# AST1080 register map
File version: 1.0
CPU: CM4 r0p1, little endian, MPU, FPU, 4 interrupt priority bits, 256 interrupts
Registers are 32-bit, read-write, reset 0x0 unless marked. A register's access mark holds for its fields unless they carry their own. Offsets are from the block's base; [hi:lo] are bit positions; {n}, {i} and the like mark numbered series.

## pric_io (part 1 of 3)
Base 0x74100000
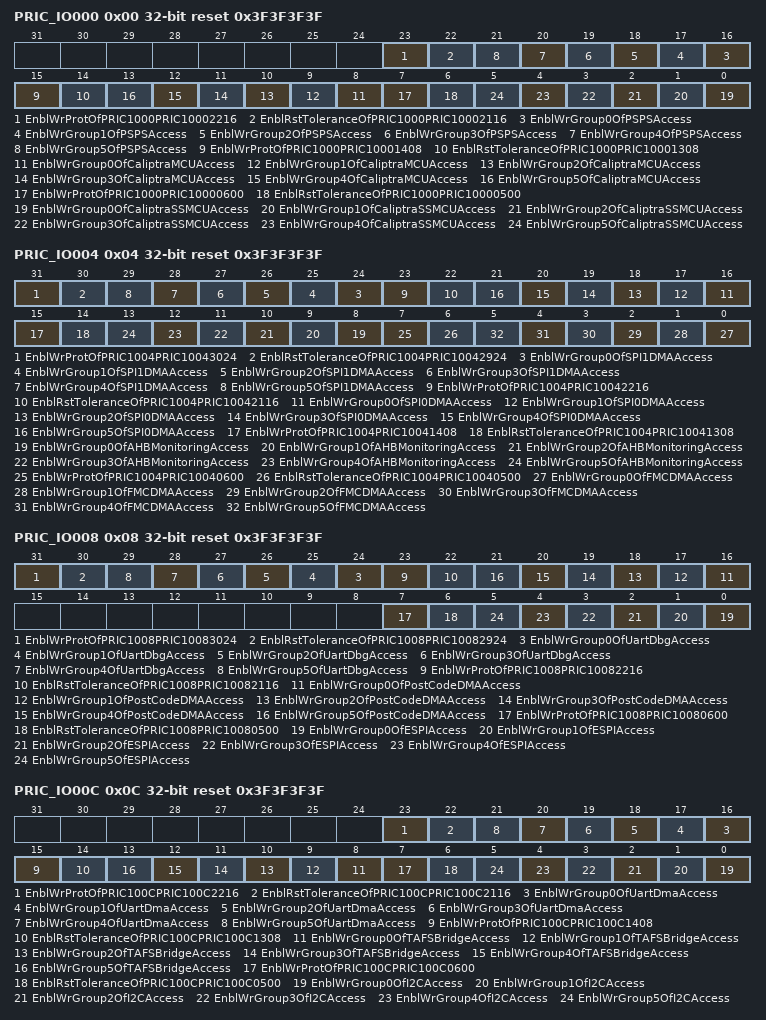
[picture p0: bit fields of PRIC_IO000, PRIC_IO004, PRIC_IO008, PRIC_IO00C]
0x00 PRIC_IO000 reset 0x3F3F3F3F — Master Write Group Setting Register \#0
  [23] EnblWrProtOfPRIC1000PRIC10002216 — Enable Write Protection of PRIC1000PRIC1_000[22:16]
  [22] EnblRstToleranceOfPRIC1000PRIC10002116 — Enable Reset Tolerance of PRIC1000PRIC1_000[21:16]
    0=Reset_By_SRST; 1=Reset_By_SRST_And_PSP_Reset
  [n+16] EnblWrGroup{n}OfPSPSAccess (n=0..5) — Enable Write Group #{n} of PSP-S access
  [15] EnblWrProtOfPRIC1000PRIC10001408 — Enable Write Protection of PRIC1000PRIC1_000[14:08]
  [14] EnblRstToleranceOfPRIC1000PRIC10001308 — Enable Reset Tolerance of PRIC1000PRIC1_000[13:08]
    0=Reset_By_SRST; 1=Reset_By_SRST_And_PSP_Reset
  [n+8] EnblWrGroup{n}OfCaliptraMCUAccess (n=0..5) — Enable Write Group #{n} of Caliptra MCU access
  [7] EnblWrProtOfPRIC1000PRIC10000600 — Enable Write Protection of PRIC1000PRIC1_000[06:00]
  [6] EnblRstToleranceOfPRIC1000PRIC10000500 — Enable Reset Tolerance of PRIC1000PRIC1_000[05:00]
    0=Reset_By_SRST; 1=Reset_By_SRST_And_PSP_Reset
  [n] EnblWrGroup{n}OfCaliptraSSMCUAccess (n=0..5) — Enable Write Group #{n} of Caliptra SS MCU access
0x04 PRIC_IO004 reset 0x3F3F3F3F — Master Write Group Setting Register \#1
  [31] EnblWrProtOfPRIC1004PRIC10043024 — Enable Write Protection of PRIC1004PRIC1_004[30:24]
  [30] EnblRstToleranceOfPRIC1004PRIC10042924 — Enable Reset Tolerance of PRIC1004PRIC1_004[29:24]
    0=Reset_By_SRST; 1=Reset_By_SRST_And_PSP_Reset
  [n+24] EnblWrGroup{n}OfSPI1DMAAccess (n=0..5) — Enable Write Group #{n} of SPI1 DMA access
  [23] EnblWrProtOfPRIC1004PRIC10042216 — Enable Write Protection of PRIC1004PRIC1_004[22:16]
  [22] EnblRstToleranceOfPRIC1004PRIC10042116 — Enable Reset Tolerance of PRIC1004PRIC1_004[21:16]
    0=Reset_By_SRST; 1=Reset_By_SRST_And_PSP_Reset
  [n+16] EnblWrGroup{n}OfSPI0DMAAccess (n=0..5) — Enable Write Group #{n} of SPI0 DMA access
  [15] EnblWrProtOfPRIC1004PRIC10041408 — Enable Write Protection of PRIC1004PRIC1_004[14:08]
  [14] EnblRstToleranceOfPRIC1004PRIC10041308 — Enable Reset Tolerance of PRIC1004PRIC1_004[13:08]
    0=Reset_By_SRST; 1=Reset_By_SRST_And_PSP_Reset
  [n+8] EnblWrGroup{n}OfAHBMonitoringAccess (n=0..5) — Enable Write Group #{n} of AHB Monitoring access
  [7] EnblWrProtOfPRIC1004PRIC10040600 — Enable Write Protection of PRIC1004PRIC1_004[06:00]
  [6] EnblRstToleranceOfPRIC1004PRIC10040500 — Enable Reset Tolerance of PRIC1004PRIC1_004[05:00]
    0=Reset_By_SRST; 1=Reset_By_SRST_And_PSP_Reset
  [n] EnblWrGroup{n}OfFMCDMAAccess (n=0..5) — Enable Write Group #{n} of FMC DMA access
0x08 PRIC_IO008 reset 0x3F3F3F3F — Master Write Group Setting Register \#2
  [31] EnblWrProtOfPRIC1008PRIC10083024 — Enable Write Protection of PRIC1008PRIC1_008[30:24]
  [30] EnblRstToleranceOfPRIC1008PRIC10082924 — Enable Reset Tolerance of PRIC1008PRIC1_008[29:24]
    0=Reset_By_SRST; 1=Reset_By_SRST_And_PSP_Reset
  [n+24] EnblWrGroup{n}OfUartDbgAccess (n=0..5) — Enable Write Group #{n} of UartDbg access
  [23] EnblWrProtOfPRIC1008PRIC10082216 — Enable Write Protection of PRIC1008PRIC1_008[22:16]
  [22] EnblRstToleranceOfPRIC1008PRIC10082116 — Enable Reset Tolerance of PRIC1008PRIC1_008[21:16]
    0=Reset_By_SRST; 1=Reset_By_SRST_And_PSP_Reset
  [n+16] EnblWrGroup{n}OfPostCodeDMAAccess (n=0..5) — Enable Write Group #{n} of PostCode DMA access
  [7] EnblWrProtOfPRIC1008PRIC10080600 — Enable Write Protection of PRIC1008PRIC1_008[06:00]
  [6] EnblRstToleranceOfPRIC1008PRIC10080500 — Enable Reset Tolerance of PRIC1008PRIC1_008[05:00]
    0=Reset_By_SRST; 1=Reset_By_SRST_And_PSP_Reset
  [n] EnblWrGroup{n}OfESPIAccess (n=0..5) — Enable Write Group #{n} of eSPI access
0x0C PRIC_IO00C reset 0x3F3F3F3F — Master Write Group Setting Register \#3
  [23] EnblWrProtOfPRIC100CPRIC100C2216 — Enable Write Protection of PRIC100CPRIC1_00C[22:16]
  [22] EnblRstToleranceOfPRIC100CPRIC100C2116 — Enable Reset Tolerance of PRIC100CPRIC1_00C[21:16]
    0=Reset_By_SRST; 1=Reset_By_SRST_And_PSP_Reset
  [n+16] EnblWrGroup{n}OfUartDmaAccess (n=0..5) — Enable Write Group #{n} of UartDma access
  [15] EnblWrProtOfPRIC100CPRIC100C1408 — Enable Write Protection of PRIC100CPRIC1_00C[14:08]
  [14] EnblRstToleranceOfPRIC100CPRIC100C1308 — Enable Reset Tolerance of PRIC100CPRIC1_00C[13:08]
    0=Reset_By_SRST; 1=Reset_By_SRST_And_PSP_Reset
  [n+8] EnblWrGroup{n}OfTAFSBridgeAccess (n=0..5) — Enable Write Group #{n} of TAFS Bridge access
  [7] EnblWrProtOfPRIC100CPRIC100C0600 — Enable Write Protection of PRIC100CPRIC1_00C[06:00]
  [6] EnblRstToleranceOfPRIC100CPRIC100C0500 — Enable Reset Tolerance of PRIC100CPRIC1_00C[05:00]
    0=Reset_By_SRST; 1=Reset_By_SRST_And_PSP_Reset
  [n] EnblWrGroup{n}OfI2CAccess (n=0..5) — Enable Write Group #{n} of I2C access
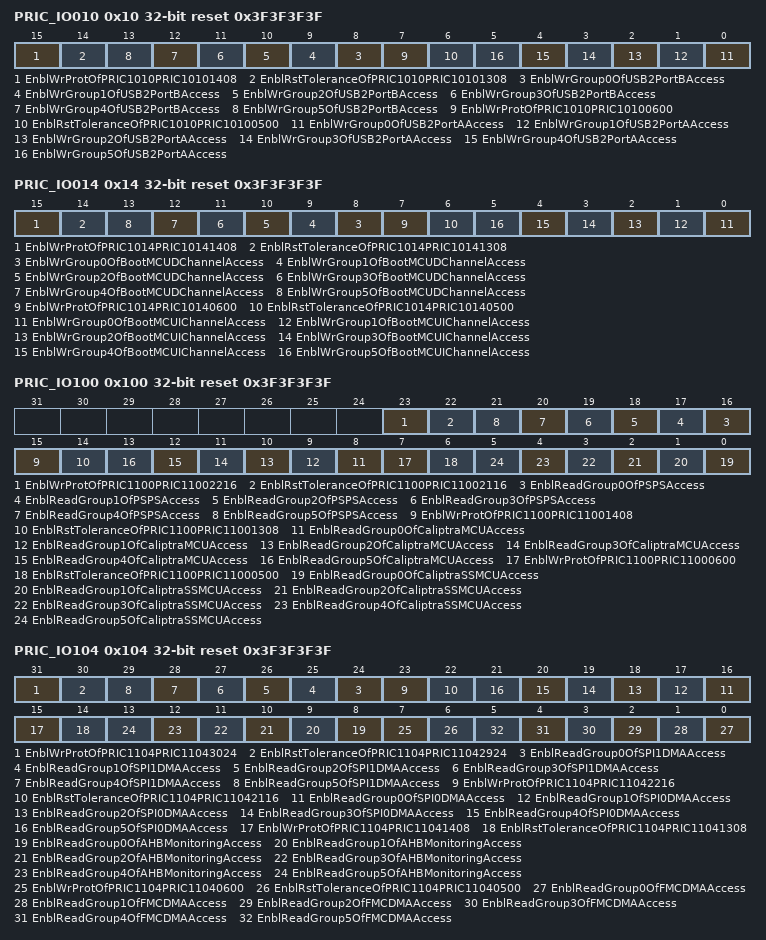
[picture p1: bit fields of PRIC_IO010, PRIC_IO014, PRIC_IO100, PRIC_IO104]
0x10 PRIC_IO010 reset 0x3F3F3F3F — Master Write Group Setting Register \#4
  [15] EnblWrProtOfPRIC1010PRIC10101408 — Enable Write Protection of PRIC1010PRIC1_010[14:08]
  [14] EnblRstToleranceOfPRIC1010PRIC10101308 — Enable Reset Tolerance of PRIC1010PRIC1_010[13:08]
    0=Reset_By_SRST; 1=Reset_By_SRST_And_PSP_Reset
  [n+8] EnblWrGroup{n}OfUSB2PortBAccess (n=0..5) — Enable Write Group #{n} of USB2 Port B access
  [7] EnblWrProtOfPRIC1010PRIC10100600 — Enable Write Protection of PRIC1010PRIC1_010[06:00]
  [6] EnblRstToleranceOfPRIC1010PRIC10100500 — Enable Reset Tolerance of PRIC1010PRIC1_010[05:00]
    0=Reset_By_SRST; 1=Reset_By_SRST_And_PSP_Reset
  [n] EnblWrGroup{n}OfUSB2PortAAccess (n=0..5) — Enable Write Group #{n} of USB2 Port A access
0x14 PRIC_IO014 reset 0x3F3F3F3F — Master Write Group Setting Register \#5
  [15] EnblWrProtOfPRIC1014PRIC10141408 — Enable Write Protection of PRIC1014PRIC1_014[14:08]
  [14] EnblRstToleranceOfPRIC1014PRIC10141308 — Enable Reset Tolerance of PRIC1014PRIC1_014[13:08]
    0=Reset_By_SRST; 1=Reset_By_SRST_And_PSP_Reset
  [n+8] EnblWrGroup{n}OfBootMCUDChannelAccess (n=0..5) — Enable Write Group #{n} of Boot MCU D channel access
  [7] EnblWrProtOfPRIC1014PRIC10140600 — Enable Write Protection of PRIC1014PRIC1_014[06:00]
  [6] EnblRstToleranceOfPRIC1014PRIC10140500 — Enable Reset Tolerance of PRIC1014PRIC1_014[05:00]
    0=Reset_By_SRST; 1=Reset_By_SRST_And_PSP_Reset
  [n] EnblWrGroup{n}OfBootMCUIChannelAccess (n=0..5) — Enable Write Group #{n} of Boot MCU I channel access
0x100 PRIC_IO100 reset 0x3F3F3F3F — Master Read Group Setting Register \#0
  [23] EnblWrProtOfPRIC1100PRIC11002216 — Enable Write Protection of PRIC1100PRIC1_100[22:16]
  [22] EnblRstToleranceOfPRIC1100PRIC11002116 — Enable Reset Tolerance of PRIC1100PRIC1_100[21:16]
    0=Reset_By_SRST; 1=Reset_By_SRST_And_PSP_Reset
  [n+16] EnblReadGroup{n}OfPSPSAccess (n=0..5) — Enable Read Group #{n} of PSP-S access
  [15] EnblWrProtOfPRIC1100PRIC11001408 — Enable Write Protection of PRIC1100PRIC1_100[14:08]
  [14] EnblRstToleranceOfPRIC1100PRIC11001308 — Enable Reset Tolerance of PRIC1100PRIC1_100[13:08]
    0=Reset_By_SRST; 1=Reset_By_SRST_And_PSP_Reset
  [n+8] EnblReadGroup{n}OfCaliptraMCUAccess (n=0..5) — Enable Read Group #{n} of Caliptra MCU access
  [7] EnblWrProtOfPRIC1100PRIC11000600 — Enable Write Protection of PRIC1100PRIC1_100[06:00]
  [6] EnblRstToleranceOfPRIC1100PRIC11000500 — Enable Reset Tolerance of PRIC1100PRIC1_100[05:00]
    0=Reset_By_SRST; 1=Reset_By_SRST_And_PSP_Reset
  [n] EnblReadGroup{n}OfCaliptraSSMCUAccess (n=0..5) — Enable Read Group #{n} of Caliptra SS MCU access
0x104 PRIC_IO104 reset 0x3F3F3F3F — Master Read Group Setting Register \#1
  [31] EnblWrProtOfPRIC1104PRIC11043024 — Enable Write Protection of PRIC1104PRIC1_104[30:24]
  [30] EnblRstToleranceOfPRIC1104PRIC11042924 — Enable Reset Tolerance of PRIC1104PRIC1_104[29:24]
    0=Reset_By_SRST; 1=Reset_By_SRST_And_PSP_Reset
  [n+24] EnblReadGroup{n}OfSPI1DMAAccess (n=0..5) — Enable Read Group #{n} of SPI1 DMA access
  [23] EnblWrProtOfPRIC1104PRIC11042216 — Enable Write Protection of PRIC1104PRIC1_104[22:16]
  [22] EnblRstToleranceOfPRIC1104PRIC11042116 — Enable Reset Tolerance of PRIC1104PRIC1_104[21:16]
    0=Reset_By_SRST; 1=Reset_By_SRST_And_PSP_Reset
  [n+16] EnblReadGroup{n}OfSPI0DMAAccess (n=0..5) — Enable Read Group #{n} of SPI0 DMA access
  [15] EnblWrProtOfPRIC1104PRIC11041408 — Enable Write Protection of PRIC1104PRIC1_104[14:08]
  [14] EnblRstToleranceOfPRIC1104PRIC11041308 — Enable Reset Tolerance of PRIC1104PRIC1_104[13:08]
    0=Reset_By_SRST; 1=Reset_By_SRST_And_PSP_Reset
  [n+8] EnblReadGroup{n}OfAHBMonitoringAccess (n=0..5) — Enable Read Group #{n} of AHB Monitoring access
  [7] EnblWrProtOfPRIC1104PRIC11040600 — Enable Write Protection of PRIC1104PRIC1_104[06:00]
  [6] EnblRstToleranceOfPRIC1104PRIC11040500 — Enable Reset Tolerance of PRIC1104PRIC1_104[05:00]
    0=Reset_By_SRST; 1=Reset_By_SRST_And_PSP_Reset
  [n] EnblReadGroup{n}OfFMCDMAAccess (n=0..5) — Enable Read Group #{n} of FMC DMA access
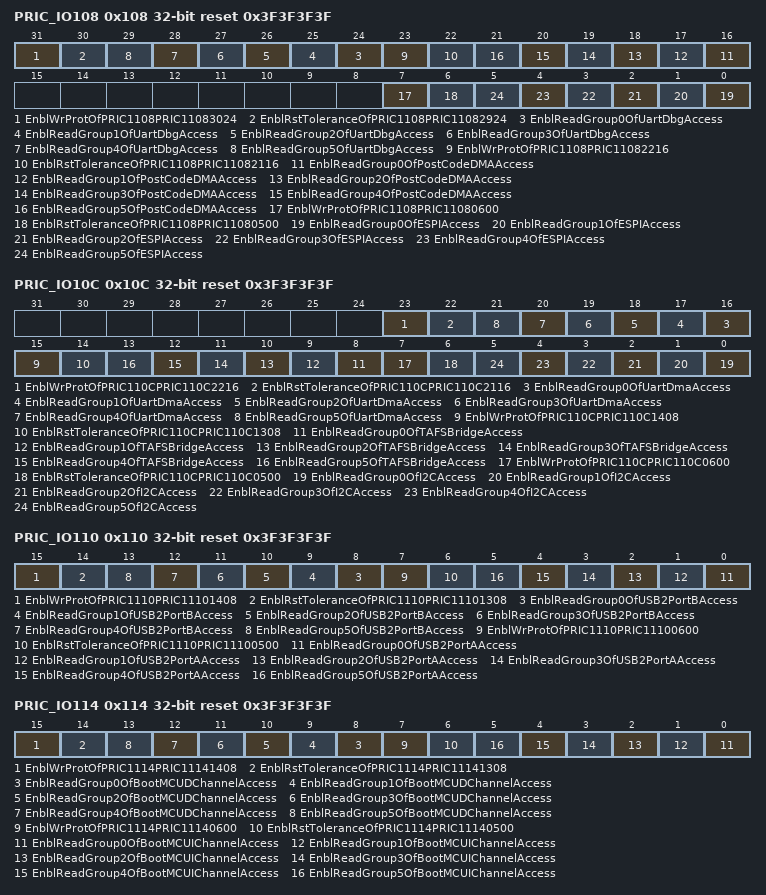
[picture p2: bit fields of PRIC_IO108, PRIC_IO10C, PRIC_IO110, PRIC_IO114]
0x108 PRIC_IO108 reset 0x3F3F3F3F — Master Read Group Setting Register \#2
  [31] EnblWrProtOfPRIC1108PRIC11083024 — Enable Write Protection of PRIC1108PRIC1_108[30:24]
  [30] EnblRstToleranceOfPRIC1108PRIC11082924 — Enable Reset Tolerance of PRIC1108PRIC1_108[29:24]
    0=Reset_By_SRST; 1=Reset_By_SRST_And_PSP_Reset
  [n+24] EnblReadGroup{n}OfUartDbgAccess (n=0..5) — Enable Read Group #{n} of UartDbg access
  [23] EnblWrProtOfPRIC1108PRIC11082216 — Enable Write Protection of PRIC1108PRIC1_108[22:16]
  [22] EnblRstToleranceOfPRIC1108PRIC11082116 — Enable Reset Tolerance of PRIC1108PRIC1_108[21:16]
    0=Reset_By_SRST; 1=Reset_By_SRST_And_PSP_Reset
  [n+16] EnblReadGroup{n}OfPostCodeDMAAccess (n=0..5) — Enable Read Group #{n} of PostCode DMA access
  [7] EnblWrProtOfPRIC1108PRIC11080600 — Enable Write Protection of PRIC1108PRIC1_108[06:00]
  [6] EnblRstToleranceOfPRIC1108PRIC11080500 — Enable Reset Tolerance of PRIC1108PRIC1_108[05:00]
    0=Reset_By_SRST; 1=Reset_By_SRST_And_PSP_Reset
  [n] EnblReadGroup{n}OfESPIAccess (n=0..5) — Enable Read Group #{n} of eSPI access
0x10C PRIC_IO10C reset 0x3F3F3F3F — Master Read Group Setting Register \#3
  [23] EnblWrProtOfPRIC110CPRIC110C2216 — Enable Write Protection of PRIC110CPRIC1_10C[22:16]
  [22] EnblRstToleranceOfPRIC110CPRIC110C2116 — Enable Reset Tolerance of PRIC110CPRIC1_10C[21:16]
    0=Reset_By_SRST; 1=Reset_By_SRST_And_PSP_Reset
  [n+16] EnblReadGroup{n}OfUartDmaAccess (n=0..5) — Enable Read Group #{n} of UartDma access
  [15] EnblWrProtOfPRIC110CPRIC110C1408 — Enable Write Protection of PRIC110CPRIC1_10C[14:08]
  [14] EnblRstToleranceOfPRIC110CPRIC110C1308 — Enable Reset Tolerance of PRIC110CPRIC1_10C[13:08]
    0=Reset_By_SRST; 1=Reset_By_SRST_And_PSP_Reset
  [n+8] EnblReadGroup{n}OfTAFSBridgeAccess (n=0..5) — Enable Read Group #{n} of TAFS Bridge access
  [7] EnblWrProtOfPRIC110CPRIC110C0600 — Enable Write Protection of PRIC110CPRIC1_10C[06:00]
  [6] EnblRstToleranceOfPRIC110CPRIC110C0500 — Enable Reset Tolerance of PRIC110CPRIC1_10C[05:00]
    0=Reset_By_SRST; 1=Reset_By_SRST_And_PSP_Reset
  [n] EnblReadGroup{n}OfI2CAccess (n=0..5) — Enable Read Group #{n} of I2C access
0x110 PRIC_IO110 reset 0x3F3F3F3F — Master Read Group Setting Register \#4
  [15] EnblWrProtOfPRIC1110PRIC11101408 — Enable Write Protection of PRIC1110PRIC1_110[14:08]
  [14] EnblRstToleranceOfPRIC1110PRIC11101308 — Enable Reset Tolerance of PRIC1110PRIC1_110[13:08]
    0=Reset_By_SRST; 1=Reset_By_SRST_And_PSP_Reset
  [n+8] EnblReadGroup{n}OfUSB2PortBAccess (n=0..5) — Enable Read Group #{n} of USB2 Port B access
  [7] EnblWrProtOfPRIC1110PRIC11100600 — Enable Write Protection of PRIC1110PRIC1_110[06:00]
  [6] EnblRstToleranceOfPRIC1110PRIC11100500 — Enable Reset Tolerance of PRIC1110PRIC1_110[05:00]
    0=Reset_By_SRST; 1=Reset_By_SRST_And_PSP_Reset
  [n] EnblReadGroup{n}OfUSB2PortAAccess (n=0..5) — Enable Read Group #{n} of USB2 Port A access
0x114 PRIC_IO114 reset 0x3F3F3F3F — Master Read Group Setting Register \#5
  [15] EnblWrProtOfPRIC1114PRIC11141408 — Enable Write Protection of PRIC1114PRIC1_114[14:08]
  [14] EnblRstToleranceOfPRIC1114PRIC11141308 — Enable Reset Tolerance of PRIC1114PRIC1_114[13:08]
    0=Reset_By_SRST; 1=Reset_By_SRST_And_PSP_Reset
  [n+8] EnblReadGroup{n}OfBootMCUDChannelAccess (n=0..5) — Enable Read Group #{n} of Boot MCU D channel access
  [7] EnblWrProtOfPRIC1114PRIC11140600 — Enable Write Protection of PRIC1114PRIC1_114[06:00]
  [6] EnblRstToleranceOfPRIC1114PRIC11140500 — Enable Reset Tolerance of PRIC1114PRIC1_114[05:00]
    0=Reset_By_SRST; 1=Reset_By_SRST_And_PSP_Reset
  [n] EnblReadGroup{n}OfBootMCUIChannelAccess (n=0..5) — Enable Read Group #{n} of Boot MCU I channel access
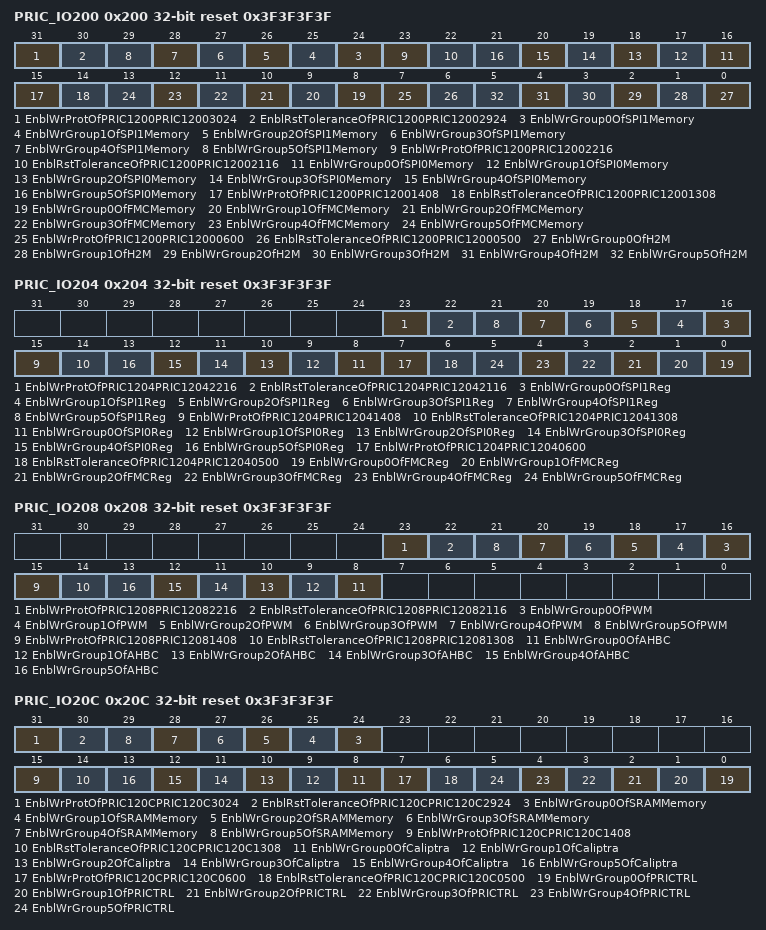
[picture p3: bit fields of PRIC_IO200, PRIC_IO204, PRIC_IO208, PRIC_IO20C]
0x200 PRIC_IO200 reset 0x3F3F3F3F — Slave Write Group Setting Register \#0
  [31] EnblWrProtOfPRIC1200PRIC12003024 — Enable Write Protection of PRIC1200PRIC1_200[30:24]
  [30] EnblRstToleranceOfPRIC1200PRIC12002924 — Enable Reset Tolerance of PRIC1200PRIC1_200[29:24]
    0=Reset_By_SRST; 1=Reset_By_SRST_And_PSP_Reset
  [n+24] EnblWrGroup{n}OfSPI1Memory (n=0..5) — Enable Write Group #{n} of SPI1 Memory
  [23] EnblWrProtOfPRIC1200PRIC12002216 — Enable Write Protection of PRIC1200PRIC1_200[22:16]
  [22] EnblRstToleranceOfPRIC1200PRIC12002116 — Enable Reset Tolerance of PRIC1200PRIC1_200[21:16]
    0=Reset_By_SRST; 1=Reset_By_SRST_And_PSP_Reset
  [n+16] EnblWrGroup{n}OfSPI0Memory (n=0..5) — Enable Write Group #{n} of SPI0 Memory
  [15] EnblWrProtOfPRIC1200PRIC12001408 — Enable Write Protection of PRIC1200PRIC1_200[14:08]
  [14] EnblRstToleranceOfPRIC1200PRIC12001308 — Enable Reset Tolerance of PRIC1200PRIC1_200[13:08]
    0=Reset_By_SRST; 1=Reset_By_SRST_And_PSP_Reset
  [n+8] EnblWrGroup{n}OfFMCMemory (n=0..5) — Enable Write Group #{n} of FMC Memory
  [7] EnblWrProtOfPRIC1200PRIC12000600 — Enable Write Protection of PRIC1200PRIC1_200[06:00]
  [6] EnblRstToleranceOfPRIC1200PRIC12000500 — Enable Reset Tolerance of PRIC1200PRIC1_200[05:00]
    0=Reset_By_SRST; 1=Reset_By_SRST_And_PSP_Reset
  [n] EnblWrGroup{n}OfH2M (n=0..5) — Enable Write Group #{n} of H2M
0x204 PRIC_IO204 reset 0x3F3F3F3F — Slave Write Group Setting Register \#1
  [23] EnblWrProtOfPRIC1204PRIC12042216 — Enable Write Protection of PRIC1204PRIC1_204[22:16]
  [22] EnblRstToleranceOfPRIC1204PRIC12042116 — Enable Reset Tolerance of PRIC1204PRIC1_204[21:16]
    0=Reset_By_SRST; 1=Reset_By_SRST_And_PSP_Reset
  [n+16] EnblWrGroup{n}OfSPI1Reg (n=0..5) — Enable Write Group #{n} of SPI1 Register
  [15] EnblWrProtOfPRIC1204PRIC12041408 — Enable Write Protection of PRIC1204PRIC1_204[14:08]
  [14] EnblRstToleranceOfPRIC1204PRIC12041308 — Enable Reset Tolerance of PRIC1204PRIC1_204[13:08]
    0=Reset_By_SRST; 1=Reset_By_SRST_And_PSP_Reset
  [n+8] EnblWrGroup{n}OfSPI0Reg (n=0..5) — Enable Write Group #{n} of SPI0 Register
  [7] EnblWrProtOfPRIC1204PRIC12040600 — Enable Write Protection of PRIC1204PRIC1_204[06:00]
  [6] EnblRstToleranceOfPRIC1204PRIC12040500 — Enable Reset Tolerance of PRIC1204PRIC1_204[05:00]
    0=Reset_By_SRST; 1=Reset_By_SRST_And_PSP_Reset
  [n] EnblWrGroup{n}OfFMCReg (n=0..5) — Enable Write Group #{n} of FMC Register
0x208 PRIC_IO208 reset 0x3F3F3F3F — Slave Write Group Setting Register \#2
  [23] EnblWrProtOfPRIC1208PRIC12082216 — Enable Write Protection of PRIC1208PRIC1_208[22:16]
  [22] EnblRstToleranceOfPRIC1208PRIC12082116 — Enable Reset Tolerance of PRIC1208PRIC1_208[21:16]
    0=Reset_By_SRST; 1=Reset_By_SRST_And_PSP_Reset
  [n+16] EnblWrGroup{n}OfPWM (n=0..5) — Enable Write Group #{n} of PWM
  [15] EnblWrProtOfPRIC1208PRIC12081408 — Enable Write Protection of PRIC1208PRIC1_208[14:08]
  [14] EnblRstToleranceOfPRIC1208PRIC12081308 — Enable Reset Tolerance of PRIC1208PRIC1_208[13:08]
    0=Reset_By_SRST; 1=Reset_By_SRST_And_PSP_Reset
  [n+8] EnblWrGroup{n}OfAHBC (n=0..5) — Enable Write Group #{n} of AHBC
0x20C PRIC_IO20C reset 0x3F3F3F3F — Slave Write Group Setting Register \#3
  [31] EnblWrProtOfPRIC120CPRIC120C3024 — Enable Write Protection of PRIC120CPRIC1_20C[30:24]
  [30] EnblRstToleranceOfPRIC120CPRIC120C2924 — Enable Reset Tolerance of PRIC120CPRIC1_20C[29:24]
    0=Reset_By_SRST; 1=Reset_By_SRST_And_PSP_Reset
  [n+24] EnblWrGroup{n}OfSRAMMemory (n=0..5) — Enable Write Group #{n} of SRAM Memory
  [15] EnblWrProtOfPRIC120CPRIC120C1408 — Enable Write Protection of PRIC120CPRIC1_20C[14:08]
  [14] EnblRstToleranceOfPRIC120CPRIC120C1308 — Enable Reset Tolerance of PRIC120CPRIC1_20C[13:08]
    0=Reset_By_SRST; 1=Reset_By_SRST_And_PSP_Reset
  [n+8] EnblWrGroup{n}OfCaliptra (n=0..5) — Enable Write Group #{n} of Caliptra
  [7] EnblWrProtOfPRIC120CPRIC120C0600 — Enable Write Protection of PRIC120CPRIC1_20C[06:00]
  [6] EnblRstToleranceOfPRIC120CPRIC120C0500 — Enable Reset Tolerance of PRIC120CPRIC1_20C[05:00]
    0=Reset_By_SRST; 1=Reset_By_SRST_And_PSP_Reset
  [n] EnblWrGroup{n}OfPRICTRL (n=0..5) — Enable Write Group #{n} of PRICTRL
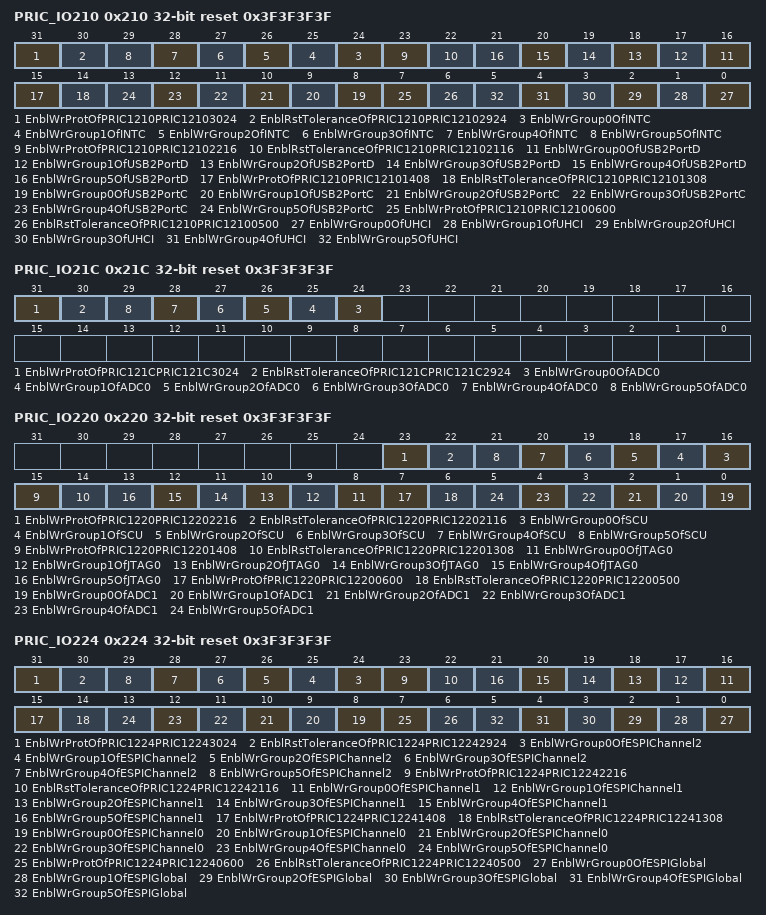
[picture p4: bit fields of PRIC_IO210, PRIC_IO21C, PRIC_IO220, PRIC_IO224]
0x210 PRIC_IO210 reset 0x3F3F3F3F — Slave Write Group Setting Register \#4
  [31] EnblWrProtOfPRIC1210PRIC12103024 — Enable Write Protection of PRIC1210PRIC1_210[30:24]
  [30] EnblRstToleranceOfPRIC1210PRIC12102924 — Enable Reset Tolerance of PRIC1210PRIC1_210[29:24]
    0=Reset_By_SRST; 1=Reset_By_SRST_And_PSP_Reset
  [n+24] EnblWrGroup{n}OfINTC (n=0..5) — Enable Write Group #{n} of INTC
  [23] EnblWrProtOfPRIC1210PRIC12102216 — Enable Write Protection of PRIC1210PRIC1_210[22:16]
  [22] EnblRstToleranceOfPRIC1210PRIC12102116 — Enable Reset Tolerance of PRIC1210PRIC1_210[21:16]
    0=Reset_By_SRST; 1=Reset_By_SRST_And_PSP_Reset
  [n+16] EnblWrGroup{n}OfUSB2PortD (n=0..5) — Enable Write Group #{n} of USB2 Port D
  [15] EnblWrProtOfPRIC1210PRIC12101408 — Enable Write Protection of PRIC1210PRIC1_210[14:08]
  [14] EnblRstToleranceOfPRIC1210PRIC12101308 — Enable Reset Tolerance of PRIC1210PRIC1_210[13:08]
    0=Reset_By_SRST; 1=Reset_By_SRST_And_PSP_Reset
  [n+8] EnblWrGroup{n}OfUSB2PortC (n=0..5) — Enable Write Group #{n} of USB2 Port C
  [7] EnblWrProtOfPRIC1210PRIC12100600 — Enable Write Protection of PRIC1210PRIC1_210[06:00]
  [6] EnblRstToleranceOfPRIC1210PRIC12100500 — Enable Reset Tolerance of PRIC1210PRIC1_210[05:00]
    0=Reset_By_SRST; 1=Reset_By_SRST_And_PSP_Reset
  [n] EnblWrGroup{n}OfUHCI (n=0..5) — Enable Write Group #{n} of UHCI
0x214 PRIC_IO214 reset 0x3F3F3F3F (reset mask 0x0) — Slave Write Group Setting Register \#5
0x218 PRIC_IO218 reset 0x3F3F3F3F (reset mask 0x0) — Slave Write Group Setting Register \#6
0x21C PRIC_IO21C reset 0x3F3F3F3F — Slave Write Group Setting Register \#7
  [31] EnblWrProtOfPRIC121CPRIC121C3024 — Enable Write Protection of PRIC121CPRIC1_21C[30:24]
  [30] EnblRstToleranceOfPRIC121CPRIC121C2924 — Enable Reset Tolerance of PRIC121CPRIC1_21C[29:24]
    0=Reset_By_SRST; 1=Reset_By_SRST_And_PSP_Reset
  [n+24] EnblWrGroup{n}OfADC0 (n=0..5) — Enable Write Group #{n} of ADC 0
0x220 PRIC_IO220 reset 0x3F3F3F3F — Slave Write Group Setting Register \#8
  [23] EnblWrProtOfPRIC1220PRIC12202216 — Enable Write Protection of PRIC1220PRIC1_220[22:16]
  [22] EnblRstToleranceOfPRIC1220PRIC12202116 — Enable Reset Tolerance of PRIC1220PRIC1_220[21:16]
    0=Reset_By_SRST; 1=Reset_By_SRST_And_PSP_Reset
  [n+16] EnblWrGroup{n}OfSCU (n=0..5) — Enable Write Group #{n} of SCU
  [15] EnblWrProtOfPRIC1220PRIC12201408 — Enable Write Protection of PRIC1220PRIC1_220[14:08]
  [14] EnblRstToleranceOfPRIC1220PRIC12201308 — Enable Reset Tolerance of PRIC1220PRIC1_220[13:08]
    0=Reset_By_SRST; 1=Reset_By_SRST_And_PSP_Reset
  [n+8] EnblWrGroup{n}OfJTAG0 (n=0..5) — Enable Write Group #{n} of JTAG0
  [7] EnblWrProtOfPRIC1220PRIC12200600 — Enable Write Protection of PRIC1220PRIC1_220[06:00]
  [6] EnblRstToleranceOfPRIC1220PRIC12200500 — Enable Reset Tolerance of PRIC1220PRIC1_220[05:00]
    0=Reset_By_SRST; 1=Reset_By_SRST_And_PSP_Reset
  [n] EnblWrGroup{n}OfADC1 (n=0..5) — Enable Write Group #{n} of ADC 1
0x224 PRIC_IO224 reset 0x3F3F3F3F — Slave Write Group Setting Register \#9
  [31] EnblWrProtOfPRIC1224PRIC12243024 — Enable Write Protection of PRIC1224PRIC1_224[30:24]
  [30] EnblRstToleranceOfPRIC1224PRIC12242924 — Enable Reset Tolerance of PRIC1224PRIC1_224[29:24]
    0=Reset_By_SRST; 1=Reset_By_SRST_And_PSP_Reset
  [n+24] EnblWrGroup{n}OfESPIChannel2 (n=0..5) — Enable Write Group #{n} of eSPI Channel 2
  [23] EnblWrProtOfPRIC1224PRIC12242216 — Enable Write Protection of PRIC1224PRIC1_224[22:16]
  [22] EnblRstToleranceOfPRIC1224PRIC12242116 — Enable Reset Tolerance of PRIC1224PRIC1_224[21:16]
    0=Reset_By_SRST; 1=Reset_By_SRST_And_PSP_Reset
  [n+16] EnblWrGroup{n}OfESPIChannel1 (n=0..5) — Enable Write Group #{n} of eSPI Channel 1
  [15] EnblWrProtOfPRIC1224PRIC12241408 — Enable Write Protection of PRIC1224PRIC1_224[14:08]
  [14] EnblRstToleranceOfPRIC1224PRIC12241308 — Enable Reset Tolerance of PRIC1224PRIC1_224[13:08]
    0=Reset_By_SRST; 1=Reset_By_SRST_And_PSP_Reset
  [n+8] EnblWrGroup{n}OfESPIChannel0 (n=0..5) — Enable Write Group #{n} of eSPI Channel 0
  [7] EnblWrProtOfPRIC1224PRIC12240600 — Enable Write Protection of PRIC1224PRIC1_224[06:00]
  [6] EnblRstToleranceOfPRIC1224PRIC12240500 — Enable Reset Tolerance of PRIC1224PRIC1_224[05:00]
    0=Reset_By_SRST; 1=Reset_By_SRST_And_PSP_Reset
  [n] EnblWrGroup{n}OfESPIGlobal (n=0..5) — Enable Write Group #{n} of eSPI Global
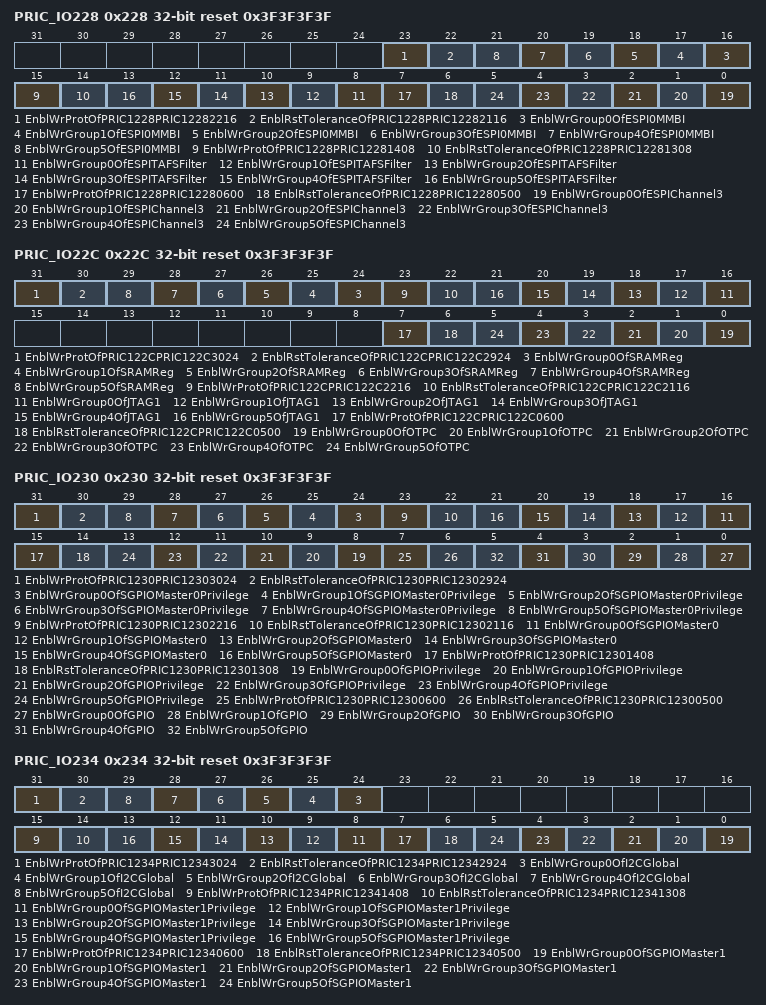
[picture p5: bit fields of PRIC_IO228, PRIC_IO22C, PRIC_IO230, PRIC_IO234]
0x228 PRIC_IO228 reset 0x3F3F3F3F — Slave Write Group Setting Register \#10
  [23] EnblWrProtOfPRIC1228PRIC12282216 — Enable Write Protection of PRIC1228PRIC1_228[22:16]
  [22] EnblRstToleranceOfPRIC1228PRIC12282116 — Enable Reset Tolerance of PRIC1228PRIC1_228[21:16]
    0=Reset_By_SRST; 1=Reset_By_SRST_And_PSP_Reset
  [n+16] EnblWrGroup{n}OfESPI0MMBI (n=0..5) — Enable Write Group #{n} of eSPI0 MMBI
  [15] EnblWrProtOfPRIC1228PRIC12281408 — Enable Write Protection of PRIC1228PRIC1_228[14:08]
  [14] EnblRstToleranceOfPRIC1228PRIC12281308 — Enable Reset Tolerance of PRIC1228PRIC1_228[13:08]
    0=Reset_By_SRST; 1=Reset_By_SRST_And_PSP_Reset
  [n+8] EnblWrGroup{n}OfESPITAFSFilter (n=0..5) — Enable Write Group #{n} of eSPI TAFS Filter
  [7] EnblWrProtOfPRIC1228PRIC12280600 — Enable Write Protection of PRIC1228PRIC1_228[06:00]
  [6] EnblRstToleranceOfPRIC1228PRIC12280500 — Enable Reset Tolerance of PRIC1228PRIC1_228[05:00]
    0=Reset_By_SRST; 1=Reset_By_SRST_And_PSP_Reset
  [n] EnblWrGroup{n}OfESPIChannel3 (n=0..5) — Enable Write Group #{n} of eSPI Channel 3
0x22C PRIC_IO22C reset 0x3F3F3F3F — Slave Write Group Setting Register \#11
  [31] EnblWrProtOfPRIC122CPRIC122C3024 — Enable Write Protection of PRIC122CPRIC1_22C[30:24]
  [30] EnblRstToleranceOfPRIC122CPRIC122C2924 — Enable Reset Tolerance of PRIC122CPRIC1_22C[29:24]
    0=Reset_By_SRST; 1=Reset_By_SRST_And_PSP_Reset
  [n+24] EnblWrGroup{n}OfSRAMReg (n=0..5) — Enable Write Group #{n} of SRAM Register
  [23] EnblWrProtOfPRIC122CPRIC122C2216 — Enable Write Protection of PRIC122CPRIC1_22C[22:16]
  [22] EnblRstToleranceOfPRIC122CPRIC122C2116 — Enable Reset Tolerance of PRIC122CPRIC1_22C[21:16]
    0=Reset_By_SRST; 1=Reset_By_SRST_And_PSP_Reset
  [n+16] EnblWrGroup{n}OfJTAG1 (n=0..5) — Enable Write Group #{n} of JTAG1
  [7] EnblWrProtOfPRIC122CPRIC122C0600 — Enable Write Protection of PRIC122CPRIC1_22C[06:00]
  [6] EnblRstToleranceOfPRIC122CPRIC122C0500 — Enable Reset Tolerance of PRIC122CPRIC1_22C[05:00]
    0=Reset_By_SRST; 1=Reset_By_SRST_And_PSP_Reset
  [n] EnblWrGroup{n}OfOTPC (n=0..5) — Enable Write Group #{n} of OTPC
0x230 PRIC_IO230 reset 0x3F3F3F3F — Slave Write Group Setting Register \#12
  [31] EnblWrProtOfPRIC1230PRIC12303024 — Enable Write Protection of PRIC1230PRIC1_230[30:24]
  [30] EnblRstToleranceOfPRIC1230PRIC12302924 — Enable Reset Tolerance of PRIC1230PRIC1_230[29:24]
    0=Reset_By_SRST; 1=Reset_By_SRST_And_PSP_Reset
  [n+24] EnblWrGroup{n}OfSGPIOMaster0Privilege (n=0..5) — Enable Write Group #{n} of SGPIO Master 0 Privilege
  [23] EnblWrProtOfPRIC1230PRIC12302216 — Enable Write Protection of PRIC1230PRIC1_230[22:16]
  [22] EnblRstToleranceOfPRIC1230PRIC12302116 — Enable Reset Tolerance of PRIC1230PRIC1_230[21:16]
    0=Reset_By_SRST; 1=Reset_By_SRST_And_PSP_Reset
  [n+16] EnblWrGroup{n}OfSGPIOMaster0 (n=0..5) — Enable Write Group #{n} of SGPIO Master 0
  [15] EnblWrProtOfPRIC1230PRIC12301408 — Enable Write Protection of PRIC1230PRIC1_230[14:08]
  [14] EnblRstToleranceOfPRIC1230PRIC12301308 — Enable Reset Tolerance of PRIC1230PRIC1_230[13:08]
    0=Reset_By_SRST; 1=Reset_By_SRST_And_PSP_Reset
  [n+8] EnblWrGroup{n}OfGPIOPrivilege (n=0..5) — Enable Write Group #{n} of GPIO Privilege
  [7] EnblWrProtOfPRIC1230PRIC12300600 — Enable Write Protection of PRIC1230PRIC1_230[06:00]
  [6] EnblRstToleranceOfPRIC1230PRIC12300500 — Enable Reset Tolerance of PRIC1230PRIC1_230[05:00]
    0=Reset_By_SRST; 1=Reset_By_SRST_And_PSP_Reset
  [n] EnblWrGroup{n}OfGPIO (n=0..5) — Enable Write Group #{n} of GPIO
0x234 PRIC_IO234 reset 0x3F3F3F3F — Slave Write Group Setting Register \#13
  [31] EnblWrProtOfPRIC1234PRIC12343024 — Enable Write Protection of PRIC1234PRIC1_234[30:24]
  [30] EnblRstToleranceOfPRIC1234PRIC12342924 — Enable Reset Tolerance of PRIC1234PRIC1_234[29:24]
    0=Reset_By_SRST; 1=Reset_By_SRST_And_PSP_Reset
  [n+24] EnblWrGroup{n}OfI2CGlobal (n=0..5) — Enable Write Group #{n} of I2C Global
  [15] EnblWrProtOfPRIC1234PRIC12341408 — Enable Write Protection of PRIC1234PRIC1_234[14:08]
  [14] EnblRstToleranceOfPRIC1234PRIC12341308 — Enable Reset Tolerance of PRIC1234PRIC1_234[13:08]
    0=Reset_By_SRST; 1=Reset_By_SRST_And_PSP_Reset
  [n+8] EnblWrGroup{n}OfSGPIOMaster1Privilege (n=0..5) — Enable Write Group #{n} of SGPIO Master 1 Privilege
  [7] EnblWrProtOfPRIC1234PRIC12340600 — Enable Write Protection of PRIC1234PRIC1_234[06:00]
  [6] EnblRstToleranceOfPRIC1234PRIC12340500 — Enable Reset Tolerance of PRIC1234PRIC1_234[05:00]
    0=Reset_By_SRST; 1=Reset_By_SRST_And_PSP_Reset
  [n] EnblWrGroup{n}OfSGPIOMaster1 (n=0..5) — Enable Write Group #{n} of SGPIO Master 1
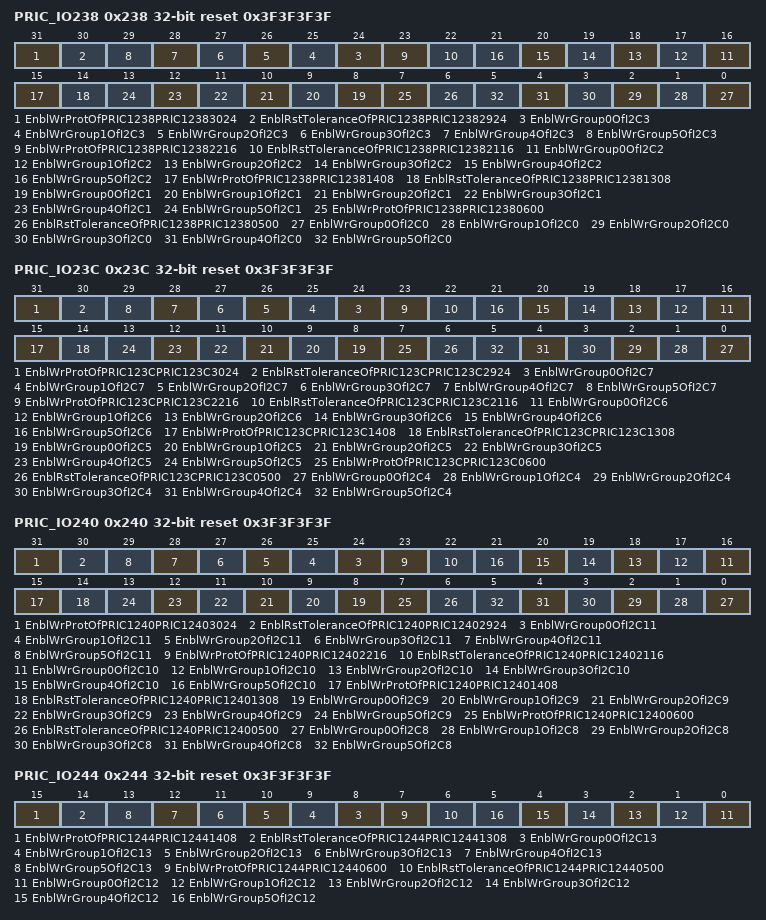
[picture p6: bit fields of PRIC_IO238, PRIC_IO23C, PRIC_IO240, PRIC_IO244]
0x238 PRIC_IO238 reset 0x3F3F3F3F — Slave Write Group Setting Register \#14
  [31] EnblWrProtOfPRIC1238PRIC12383024 — Enable Write Protection of PRIC1238PRIC1_238[30:24]
  [30] EnblRstToleranceOfPRIC1238PRIC12382924 — Enable Reset Tolerance of PRIC1238PRIC1_238[29:24]
    0=Reset_By_SRST; 1=Reset_By_SRST_And_PSP_Reset
  [n+24] EnblWrGroup{n}OfI2C3 (n=0..5) — Enable Write Group #{n} of I2C3
  [23] EnblWrProtOfPRIC1238PRIC12382216 — Enable Write Protection of PRIC1238PRIC1_238[22:16]
  [22] EnblRstToleranceOfPRIC1238PRIC12382116 — Enable Reset Tolerance of PRIC1238PRIC1_238[21:16]
    0=Reset_By_SRST; 1=Reset_By_SRST_And_PSP_Reset
  [n+16] EnblWrGroup{n}OfI2C2 (n=0..5) — Enable Write Group #{n} of I2C2
  [15] EnblWrProtOfPRIC1238PRIC12381408 — Enable Write Protection of PRIC1238PRIC1_238[14:08]
  [14] EnblRstToleranceOfPRIC1238PRIC12381308 — Enable Reset Tolerance of PRIC1238PRIC1_238[13:08]
    0=Reset_By_SRST; 1=Reset_By_SRST_And_PSP_Reset
  [n+8] EnblWrGroup{n}OfI2C1 (n=0..5) — Enable Write Group #{n} of I2C1
  [7] EnblWrProtOfPRIC1238PRIC12380600 — Enable Write Protection of PRIC1238PRIC1_238[06:00]
  [6] EnblRstToleranceOfPRIC1238PRIC12380500 — Enable Reset Tolerance of PRIC1238PRIC1_238[05:00]
    0=Reset_By_SRST; 1=Reset_By_SRST_And_PSP_Reset
  [n] EnblWrGroup{n}OfI2C0 (n=0..5) — Enable Write Group #{n} of I2C0
0x23C PRIC_IO23C reset 0x3F3F3F3F — Slave Write Group Setting Register \#15
  [31] EnblWrProtOfPRIC123CPRIC123C3024 — Enable Write Protection of PRIC123CPRIC1_23C[30:24]
  [30] EnblRstToleranceOfPRIC123CPRIC123C2924 — Enable Reset Tolerance of PRIC123CPRIC1_23C[29:24]
    0=Reset_By_SRST; 1=Reset_By_SRST_And_PSP_Reset
  [n+24] EnblWrGroup{n}OfI2C7 (n=0..5) — Enable Write Group #{n} of I2C7
  [23] EnblWrProtOfPRIC123CPRIC123C2216 — Enable Write Protection of PRIC123CPRIC1_23C[22:16]
  [22] EnblRstToleranceOfPRIC123CPRIC123C2116 — Enable Reset Tolerance of PRIC123CPRIC1_23C[21:16]
    0=Reset_By_SRST; 1=Reset_By_SRST_And_PSP_Reset
  [n+16] EnblWrGroup{n}OfI2C6 (n=0..5) — Enable Write Group #{n} of I2C6
  [15] EnblWrProtOfPRIC123CPRIC123C1408 — Enable Write Protection of PRIC123CPRIC1_23C[14:08]
  [14] EnblRstToleranceOfPRIC123CPRIC123C1308 — Enable Reset Tolerance of PRIC123CPRIC1_23C[13:08]
    0=Reset_By_SRST; 1=Reset_By_SRST_And_PSP_Reset
  [n+8] EnblWrGroup{n}OfI2C5 (n=0..5) — Enable Write Group #{n} of I2C5
  [7] EnblWrProtOfPRIC123CPRIC123C0600 — Enable Write Protection of PRIC123CPRIC1_23C[06:00]
  [6] EnblRstToleranceOfPRIC123CPRIC123C0500 — Enable Reset Tolerance of PRIC123CPRIC1_23C[05:00]
    0=Reset_By_SRST; 1=Reset_By_SRST_And_PSP_Reset
  [n] EnblWrGroup{n}OfI2C4 (n=0..5) — Enable Write Group #{n} of I2C4
0x240 PRIC_IO240 reset 0x3F3F3F3F — Slave Write Group Setting Register \#16
  [31] EnblWrProtOfPRIC1240PRIC12403024 — Enable Write Protection of PRIC1240PRIC1_240[30:24]
  [30] EnblRstToleranceOfPRIC1240PRIC12402924 — Enable Reset Tolerance of PRIC1240PRIC1_240[29:24]
    0=Reset_By_SRST; 1=Reset_By_SRST_And_PSP_Reset
  [n+24] EnblWrGroup{n}OfI2C11 (n=0..5) — Enable Write Group #{n} of I2C11
  [23] EnblWrProtOfPRIC1240PRIC12402216 — Enable Write Protection of PRIC1240PRIC1_240[22:16]
  [22] EnblRstToleranceOfPRIC1240PRIC12402116 — Enable Reset Tolerance of PRIC1240PRIC1_240[21:16]
    0=Reset_By_SRST; 1=Reset_By_SRST_And_PSP_Reset
  [n+16] EnblWrGroup{n}OfI2C10 (n=0..5) — Enable Write Group #{n} of I2C10
  [15] EnblWrProtOfPRIC1240PRIC12401408 — Enable Write Protection of PRIC1240PRIC1_240[14:08]
  [14] EnblRstToleranceOfPRIC1240PRIC12401308 — Enable Reset Tolerance of PRIC1240PRIC1_240[13:08]
    0=Reset_By_SRST; 1=Reset_By_SRST_And_PSP_Reset
  [n+8] EnblWrGroup{n}OfI2C9 (n=0..5) — Enable Write Group #{n} of I2C9
  [7] EnblWrProtOfPRIC1240PRIC12400600 — Enable Write Protection of PRIC1240PRIC1_240[06:00]
  [6] EnblRstToleranceOfPRIC1240PRIC12400500 — Enable Reset Tolerance of PRIC1240PRIC1_240[05:00]
    0=Reset_By_SRST; 1=Reset_By_SRST_And_PSP_Reset
  [n] EnblWrGroup{n}OfI2C8 (n=0..5) — Enable Write Group #{n} of I2C8
0x244 PRIC_IO244 reset 0x3F3F3F3F — Slave Write Group Setting Register \#17
  [15] EnblWrProtOfPRIC1244PRIC12441408 — Enable Write Protection of PRIC1244PRIC1_244[14:08]
  [14] EnblRstToleranceOfPRIC1244PRIC12441308 — Enable Reset Tolerance of PRIC1244PRIC1_244[13:08]
    0=Reset_By_SRST; 1=Reset_By_SRST_And_PSP_Reset
  [n+8] EnblWrGroup{n}OfI2C13 (n=0..5) — Enable Write Group #{n} of I2C13
  [7] EnblWrProtOfPRIC1244PRIC12440600 — Enable Write Protection of PRIC1244PRIC1_244[06:00]
  [6] EnblRstToleranceOfPRIC1244PRIC12440500 — Enable Reset Tolerance of PRIC1244PRIC1_244[05:00]
    0=Reset_By_SRST; 1=Reset_By_SRST_And_PSP_Reset
  [n] EnblWrGroup{n}OfI2C12 (n=0..5) — Enable Write Group #{n} of I2C12
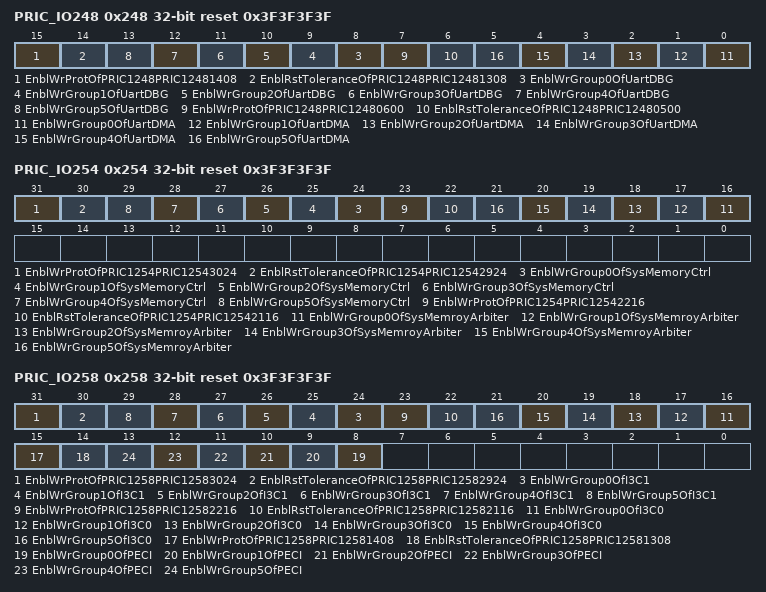
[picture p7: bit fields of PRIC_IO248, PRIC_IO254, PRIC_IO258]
0x248 PRIC_IO248 reset 0x3F3F3F3F — Slave Write Group Setting Register \#18
  [15] EnblWrProtOfPRIC1248PRIC12481408 — Enable Write Protection of PRIC1248PRIC1_248[14:08]
  [14] EnblRstToleranceOfPRIC1248PRIC12481308 — Enable Reset Tolerance of PRIC1248PRIC1_248[13:08]
    0=Reset_By_SRST; 1=Reset_By_SRST_And_PSP_Reset
  [n+8] EnblWrGroup{n}OfUartDBG (n=0..5) — Enable Write Group #{n} of UartDBG
  [7] EnblWrProtOfPRIC1248PRIC12480600 — Enable Write Protection of PRIC1248PRIC1_248[06:00]
  [6] EnblRstToleranceOfPRIC1248PRIC12480500 — Enable Reset Tolerance of PRIC1248PRIC1_248[05:00]
    0=Reset_By_SRST; 1=Reset_By_SRST_And_PSP_Reset
  [n] EnblWrGroup{n}OfUartDMA (n=0..5) — Enable Write Group #{n} of UartDMA
0x24C PRIC_IO24C reset 0x3F3F3F3F (reset mask 0x0) — Slave Write Group Setting Register \#19
0x250 PRIC_IO250 reset 0x3F3F3F3F (reset mask 0x0) — Slave Write Group Setting Register \#20
0x254 PRIC_IO254 reset 0x3F3F3F3F — Slave Write Group Setting Register \#21
  [31] EnblWrProtOfPRIC1254PRIC12543024 — Enable Write Protection of PRIC1254PRIC1_254[30:24]
  [30] EnblRstToleranceOfPRIC1254PRIC12542924 — Enable Reset Tolerance of PRIC1254PRIC1_254[29:24]
    0=Reset_By_SRST; 1=Reset_By_SRST_And_PSP_Reset
  [n+24] EnblWrGroup{n}OfSysMemoryCtrl (n=0..5) — Enable Write Group #{n} of System Memory Controller
  [23] EnblWrProtOfPRIC1254PRIC12542216 — Enable Write Protection of PRIC1254PRIC1_254[22:16]
  [22] EnblRstToleranceOfPRIC1254PRIC12542116 — Enable Reset Tolerance of PRIC1254PRIC1_254[21:16]
    0=Reset_By_SRST; 1=Reset_By_SRST_And_PSP_Reset
  [n+16] EnblWrGroup{n}OfSysMemroyArbiter (n=0..5) — Enable Write Group #{n} of System Memroy Arbiter
0x258 PRIC_IO258 reset 0x3F3F3F3F — Slave Write Group Setting Register \#22
  [31] EnblWrProtOfPRIC1258PRIC12583024 — Enable Write Protection of PRIC1258PRIC1_258[30:24]
  [30] EnblRstToleranceOfPRIC1258PRIC12582924 — Enable Reset Tolerance of PRIC1258PRIC1_258[29:24]
    0=Reset_By_SRST; 1=Reset_By_SRST_And_PSP_Reset
  [n+24] EnblWrGroup{n}OfI3C1 (n=0..5) — Enable Write Group #{n} of I3C1
  [23] EnblWrProtOfPRIC1258PRIC12582216 — Enable Write Protection of PRIC1258PRIC1_258[22:16]
  [22] EnblRstToleranceOfPRIC1258PRIC12582116 — Enable Reset Tolerance of PRIC1258PRIC1_258[21:16]
    0=Reset_By_SRST; 1=Reset_By_SRST_And_PSP_Reset
  [n+16] EnblWrGroup{n}OfI3C0 (n=0..5) — Enable Write Group #{n} of I3C0
  [15] EnblWrProtOfPRIC1258PRIC12581408 — Enable Write Protection of PRIC1258PRIC1_258[14:08]
  [14] EnblRstToleranceOfPRIC1258PRIC12581308 — Enable Reset Tolerance of PRIC1258PRIC1_258[13:08]
    0=Reset_By_SRST; 1=Reset_By_SRST_And_PSP_Reset
  [n+8] EnblWrGroup{n}OfPECI (n=0..5) — Enable Write Group #{n} of PECI
